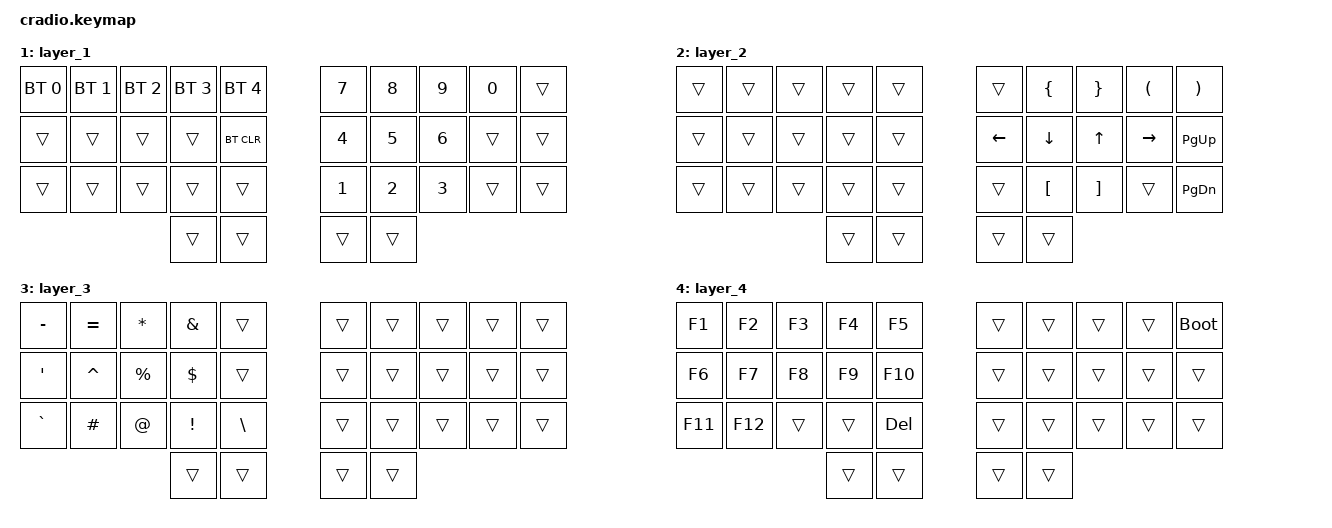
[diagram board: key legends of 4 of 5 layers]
// Copyright (c) 2022 The ZMK Contributors
// SPDX-License-Identifier: MIT

#include <behaviors.dtsi>
#include <dt-bindings/zmk/keys.h>
#include <dt-bindings/zmk/bt.h>

// Home row mods macro
#define HRML(k1,k2,k3,k4) &ht LGUI k1  &ht LALT k2  &ht LSHFT k3  &ht LCTRL k4
#define HRMR(k1,k2,k3,k4) &ht RCTRL k1  &ht RSHFT k2  &ht RALT k3  &ht RGUI k4

/ {
    behaviors {
        ht: hold_tap {
            compatible = "zmk,behavior-hold-tap";
            #binding-cells = <2>;
            flavor = "tap-preferred";
            tapping-term-ms = <220>;
            quick-tap-ms = <150>;
            require-prior-idle-ms = <100>;
            bindings = <&kp>, <&kp>;
        };
    };

    combos {
        compatible = "zmk,combos";

        esc {
            bindings = <&kp ESCAPE>;
            key-positions = <14 15>;
        };
    };

    keymap {
        compatible = "zmk,keymap";
        default_layer {
            bindings = <
        //╭──────────┬──────────┬──────────┬──────────┬──────────╮   ╭──────────┬──────────┬──────────┬──────────┬──────────╮
        //│  Q       │  W       │  E       │  R       │  T       │   │  Y       │  U       │  I       │  O       │  P       │
            &kp Q      &kp W      &kp E      &kp R      &kp T          &kp Y      &kp U      &kp I      &kp O      &kp P
        //├──────────┼──────────┼──────────┼──────────┼──────────┤   ├──────────┼──────────┼──────────┼──────────┼──────────┤
        //│  A       │  S       │  D       │  F       │  G       │   │  H       │  J       │  K       │  L       │ ; :      │
            HRML(A,        S,         D,         F)     &kp G          &kp H      HRMR(J,        K,         L,        SEMI)
        //├──────────┼──────────┼──────────┼──────────┼──────────┤   ├──────────┼──────────┼──────────┼──────────┼──────────┤
        //│  Z       │  X       │  C       │  V       │  B       │   │  N       │  M       │ , <      │ . >      │ / ?      │
            &kp Z      &kp X      &kp C      &kp V      &kp B          &kp N      &kp M      &kp COMMA  &kp DOT    &kp FSLH
        //╰──────────┴──────────┴──────────┼──────────┼──────────┤   ├──────────┼──────────┼──────────┴──────────┴──────────╯
                                             &lt 1 TAB  &lt 2 SPACE    &lt 3 ENTER &lt 4 BSPC
        //                                 ╰──────────┴──────────╯   ╰──────────┴──────────╯
            >;
        };

        layer_1 {
            bindings = <
        &bt BT_SEL 0  &bt BT_SEL 1 &bt BT_SEL 2 &bt BT_SEL 3 &bt BT_SEL 4    &kp N7  &kp N8  &kp N9  &kp N0  &trans
        &trans  &trans  &trans  &trans  &bt BT_CLR    &kp N4  &kp N5  &kp N6  &trans  &trans
        &trans  &trans  &trans  &trans  &trans    &kp N1  &kp N2  &kp N3  &trans  &trans
                                &trans  &trans    &trans  &trans
            >;
        };
        layer_2 {
            bindings = <
        &trans  &trans  &trans  &trans  &trans    &trans    &kp LEFT_BRACE    &kp RIGHT_BRACE    &kp LEFT_PARENTHESIS  &kp RIGHT_PARENTHESIS
        &trans  &trans  &trans  &trans  &trans    &kp LEFT  &kp DOWN_ARROW    &kp UP_ARROW       &kp RIGHT_ARROW       &kp PAGE_UP
        &trans  &trans  &trans  &trans  &trans    &trans    &kp LEFT_BRACKET  &kp RIGHT_BRACKET  &trans                &kp PAGE_DOWN
                                &trans  &trans    &trans    &trans
            >;
        };

        layer_3 {
            bindings = <
        &kp MINUS  &kp EQUAL      &kp ASTERISK  &kp AMPERSAND    &trans                  &trans  &trans  &trans  &trans  &trans
        &kp SQT    &kp CARET      &kp PERCENT   &kp DOLLAR       &trans                  &trans  &trans  &trans  &trans  &trans
        &kp GRAVE  &kp HASH       &kp AT_SIGN   &kp EXCLAMATION  &kp BACKSLASH           &trans  &trans  &trans  &trans  &trans
                                            &trans           &trans                  &trans  &trans
            >;
        };

        layer_4 {
            bindings = <
        &kp F1   &kp F2   &kp F3  &kp F4  &kp F5        &trans  &trans  &trans  &trans  &bootloader
        &kp F6   &kp F7   &kp F8  &kp F9  &kp F10       &trans  &trans  &trans  &trans  &trans
        &kp F11  &kp F12  &trans  &trans  &kp DELETE    &trans  &trans  &trans  &trans  &trans
                                  &trans  &trans        &trans  &trans
            >;
        };
    };
};
